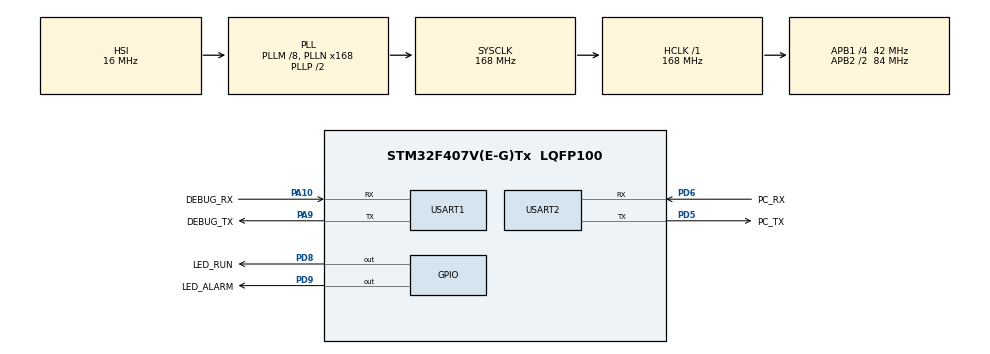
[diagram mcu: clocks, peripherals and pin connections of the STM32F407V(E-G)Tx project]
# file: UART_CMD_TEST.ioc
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Dma.Request0=USART1_RX
Dma.Request1=USART1_TX
Dma.Request2=USART2_RX
Dma.Request3=USART2_TX
Dma.USART1_RX.0.Direction=DMA_PERIPH_TO_MEMORY
Dma.USART1_RX.0.FIFOMode=DMA_FIFOMODE_DISABLE
Dma.USART1_RX.0.Instance=DMA2_Stream2
Dma.USART1_RX.0.MemDataAlignment=DMA_MDATAALIGN_BYTE
Dma.USART1_RX.0.MemInc=DMA_MINC_ENABLE
Dma.USART1_RX.0.Mode=DMA_NORMAL
Dma.USART1_RX.0.PeriphDataAlignment=DMA_PDATAALIGN_BYTE
Dma.USART1_RX.0.PeriphInc=DMA_PINC_DISABLE
Dma.USART1_RX.0.Priority=DMA_PRIORITY_HIGH
Dma.USART1_TX.1.Direction=DMA_MEMORY_TO_PERIPH
Dma.USART1_TX.1.FIFOMode=DMA_FIFOMODE_DISABLE
Dma.USART1_TX.1.Instance=DMA2_Stream7
Dma.USART1_TX.1.MemDataAlignment=DMA_MDATAALIGN_BYTE
Dma.USART1_TX.1.MemInc=DMA_MINC_ENABLE
Dma.USART1_TX.1.Mode=DMA_NORMAL
Dma.USART1_TX.1.PeriphDataAlignment=DMA_PDATAALIGN_BYTE
Dma.USART1_TX.1.PeriphInc=DMA_PINC_DISABLE
Dma.USART1_TX.1.Priority=DMA_PRIORITY_HIGH
Dma.USART2_RX.2.Direction=DMA_PERIPH_TO_MEMORY
Dma.USART2_RX.2.FIFOMode=DMA_FIFOMODE_DISABLE
Dma.USART2_RX.2.Instance=DMA1_Stream5
Dma.USART2_RX.2.MemDataAlignment=DMA_MDATAALIGN_BYTE
Dma.USART2_RX.2.MemInc=DMA_MINC_ENABLE
Dma.USART2_RX.2.Mode=DMA_NORMAL
Dma.USART2_RX.2.PeriphDataAlignment=DMA_PDATAALIGN_BYTE
Dma.USART2_RX.2.PeriphInc=DMA_PINC_DISABLE
Dma.USART2_RX.2.Priority=DMA_PRIORITY_MEDIUM
Dma.USART2_TX.3.Direction=DMA_MEMORY_TO_PERIPH
Dma.USART2_TX.3.FIFOMode=DMA_FIFOMODE_DISABLE
Dma.USART2_TX.3.Instance=DMA1_Stream6
Dma.USART2_TX.3.MemDataAlignment=DMA_MDATAALIGN_BYTE
Dma.USART2_TX.3.MemInc=DMA_MINC_ENABLE
Dma.USART2_TX.3.Mode=DMA_NORMAL
Dma.USART2_TX.3.PeriphDataAlignment=DMA_PDATAALIGN_BYTE
Dma.USART2_TX.3.PeriphInc=DMA_PINC_DISABLE
Dma.USART2_TX.3.Priority=DMA_PRIORITY_MEDIUM
FREERTOS.Mutexes01=PrintfMutex,Dynamic,NULL
FREERTOS.Queues01=U1RecvQueue,16,uint32_t,0,Dynamic,NULL,NULL;U2RecvQueue,16,uint32_t,0,Dynamic,NULL,NULL;U2SendQueue,16,uint32_t,0,Dynamic,NULL,NULL;U1SendQueue,16,uint32_t,0,Dynamic,NULL,NULL
FREERTOS.Tasks01=SysInitTask,0,512,StartSysInitTask,Default,NULL,Dynamic,NULL,NULL;DebugCmdTask,1,512,StartDebugCmdTask,Default,NULL,Dynamic,NULL,NULL;LedRunTask,0,128,StartLedRunTask,Default,NULL,Dynamic,NULL,NULL;Upload2PCTask,1,256,StartUpload2PCTask,Default,NULL,Dynamic,NULL,NULL
FREERTOS.configGENERATE_RUN_TIME_STATS=1
FREERTOS.configUSE_STATS_FORMATTING_FUNCTIONS=1
FREERTOS.configUSE_TIMERS=1
FREERTOS.configUSE_TRACE_FACILITY=1
Mcu.Family=STM32F4
Mcu.Name=STM32F407V(E-G)Tx
Mcu.Package=LQFP100
NVIC.DMA1_Stream5_IRQn=true\:5\:0\:false\:false\:true\:true\:false
NVIC.DMA1_Stream6_IRQn=true\:5\:0\:false\:false\:true\:true\:false
NVIC.DMA2_Stream2_IRQn=true\:5\:0\:false\:false\:true\:true\:false
NVIC.DMA2_Stream7_IRQn=true\:5\:0\:false\:false\:true\:true\:false
NVIC.PriorityGroup=NVIC_PRIORITYGROUP_4
NVIC.TIM5_IRQn=true\:0\:0\:false\:false\:true\:false\:false
NVIC.TIM6_DAC_IRQn=true\:5\:0\:false\:false\:true\:true\:true
NVIC.TimeBase=TIM5_IRQn
NVIC.TimeBaseIP=TIM5
NVIC.USART1_IRQn=true\:5\:0\:false\:false\:true\:true\:true
NVIC.USART2_IRQn=true\:5\:0\:false\:false\:true\:true\:true
PA10.GPIO_Label=DEBUG_RX
PA10.Mode=Asynchronous
PA10.Signal=USART1_RX
PA13.Mode=Serial_Wire
PA13.Signal=SYS_JTMS-SWDIO
PA14.Mode=Serial_Wire
PA14.Signal=SYS_JTCK-SWCLK
PA9.GPIO_Label=DEBUG_TX
PA9.Mode=Asynchronous
PA9.Signal=USART1_TX
PD5.GPIO_Label=PC_TX
PD5.Mode=Asynchronous
PD5.Signal=USART2_TX
PD6.GPIO_Label=PC_RX
PD6.Mode=Asynchronous
PD6.Signal=USART2_RX
PD8.GPIO_Label=LED_RUN
PD8.GPIO_ModeDefaultOutputPP=GPIO_MODE_OUTPUT_PP
PD8.GPIO_PuPd=GPIO_PULLDOWN
PD8.GPIO_Speed=GPIO_SPEED_FREQ_MEDIUM
PD8.PinState=GPIO_PIN_RESET
PD8.Signal=GPIO_Output
PD9.GPIO_Label=LED_ALARM
PD9.GPIO_PuPd=GPIO_PULLDOWN
PD9.GPIO_Speed=GPIO_SPEED_FREQ_MEDIUM
PD9.Signal=GPIO_Output
PH0-OSC_IN.Mode=HSE-External-Oscillator
PH0-OSC_IN.Signal=RCC_OSC_IN
PH1-OSC_OUT.Mode=HSE-External-Oscillator
PH1-OSC_OUT.Signal=RCC_OSC_OUT
ProjectManager.HeapSize=0x200
ProjectManager.StackSize=0x400
ProjectManager.TargetToolchain=MDK-ARM V5
RCC.48MHZClocksFreq_Value=84000000
RCC.AHBFreq_Value=168000000
RCC.APB1CLKDivider=RCC_HCLK_DIV4
RCC.APB1Freq_Value=42000000
RCC.APB1TimFreq_Value=84000000
RCC.APB2CLKDivider=RCC_HCLK_DIV2
RCC.APB2Freq_Value=84000000
RCC.APB2TimFreq_Value=168000000
RCC.CortexFreq_Value=168000000
RCC.HCLKFreq_Value=168000000
RCC.HSE_VALUE=8000000
RCC.HSI_VALUE=16000000
RCC.LSE_VALUE=32768
RCC.PLLM=8
RCC.PLLN=168
RCC.SYSCLKFreq_VALUE=168000000
RCC.SYSCLKSource=RCC_SYSCLKSOURCE_PLLCLK
RCC.VCOOutputFreq_Value=336000000
TIM6.Period=10
TIM6.Prescaler=84-1
USART1.VirtualMode=VM_ASYNC
USART2.VirtualMode=VM_ASYNC
VP_FREERTOS_VS_ENABLE.Mode=Enabled
VP_SYS_VS_tim5.Mode=TIM5
VP_TIM6_VS_ClockSourceINT.Mode=Enable_Timer
board=custom

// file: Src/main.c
/**
  ******************************************************************************
  * @file           : main.c
  * @brief          : Main program body
  ******************************************************************************
  * This notice applies to any and all portions of this file
  * that are not between comment pairs USER CODE BEGIN and
  * USER CODE END. Other portions of this file, whether
  * inserted by the user or by software development tools
  * are owned by their respective copyright owners.
  *
  * Copyright (c) 2020 STMicroelectronics International N.V.
  * All rights reserved.
  *
  * Redistribution and use in source and binary forms, with or without
  * modification, are permitted, provided that the following conditions are met:
  *
  * 1. Redistribution of source code must retain the above copyright notice,
  *    this list of conditions and the following disclaimer.
  * 2. Redistributions in binary form must reproduce the above copyright notice,
  *    this list of conditions and the following disclaimer in the documentation
  *    and/or other materials provided with the distribution.
  * 3. Neither the name of STMicroelectronics nor the names of other
  *    contributors to this software may be used to endorse or promote products
  *    derived from this software without specific written permission.
  * 4. This software, including modifications and/or derivative works of this
  *    software, must execute solely and exclusively on microcontroller or
  *    microprocessor devices manufactured by or for STMicroelectronics.
  * 5. Redistribution and use of this software other than as permitted under
  *    this license is void and will automatically terminate your rights under
  *    this license.
  *
  * THIS SOFTWARE IS PROVIDED BY STMICROELECTRONICS AND CONTRIBUTORS "AS IS"
  * AND ANY EXPRESS, IMPLIED OR STATUTORY WARRANTIES, INCLUDING, BUT NOT
  * LIMITED TO, THE IMPLIED WARRANTIES OF MERCHANTABILITY, FITNESS FOR A
  * PARTICULAR PURPOSE AND NON-INFRINGEMENT OF THIRD PARTY INTELLECTUAL PROPERTY
  * RIGHTS ARE DISCLAIMED TO THE FULLEST EXTENT PERMITTED BY LAW. IN NO EVENT
  * SHALL STMICROELECTRONICS OR CONTRIBUTORS BE LIABLE FOR ANY DIRECT, INDIRECT,
  * INCIDENTAL, SPECIAL, EXEMPLARY, OR CONSEQUENTIAL DAMAGES (INCLUDING, BUT NOT
  * LIMITED TO, PROCUREMENT OF SUBSTITUTE GOODS OR SERVICES; LOSS OF USE, DATA,
  * OR PROFITS; OR BUSINESS INTERRUPTION) HOWEVER CAUSED AND ON ANY THEORY OF
  * LIABILITY, WHETHER IN CONTRACT, STRICT LIABILITY, OR TORT (INCLUDING
  * NEGLIGENCE OR OTHERWISE) ARISING IN ANY WAY OUT OF THE USE OF THIS SOFTWARE,
  * EVEN IF ADVISED OF THE POSSIBILITY OF SUCH DAMAGE.
  *
  ******************************************************************************
  */
#include "main.h"
#include "stm32f4xx_hal.h"
#include "cmsis_os.h"
#include "dma.h"
#include "tim.h"
#include "usart.h"
#include "gpio.h"

/* USER CODE BEGIN PV */
/* Private variables ---------------------------------------------------------*/
extern volatile unsigned long  ulHighFrequencyTimerTicks;
/* USER CODE END PV */

void SystemClock_Config(void);
void MX_FREERTOS_Init(void);

/* USER CODE BEGIN PFP */
/* Private function prototypes -----------------------------------------------*/

/* USER CODE END PFP */

int main(void)
{

  /* MCU Configuration----------------------------------------------------------*/

  /* Reset of all peripherals, Initializes the Flash interface and the Systick. */
  HAL_Init();

  /* Configure the system clock */
  SystemClock_Config();

  /* Initialize all configured peripherals */
  MX_GPIO_Init();
  MX_DMA_Init();
  MX_USART1_UART_Init();
  MX_USART2_UART_Init();
  MX_TIM6_Init();

  /* Call init function for freertos objects (in freertos.c) */
  MX_FREERTOS_Init();

  /* Start scheduler */
  osKernelStart();

  /* We should never get here as control is now taken by the scheduler */

  /* Infinite loop */
  while (1)
  {

  }

}

void SystemClock_Config(void)
{

  RCC_OscInitTypeDef RCC_OscInitStruct;
  RCC_ClkInitTypeDef RCC_ClkInitStruct;

    /**Configure the main internal regulator output voltage
    */
  __HAL_RCC_PWR_CLK_ENABLE();

  __HAL_PWR_VOLTAGESCALING_CONFIG(PWR_REGULATOR_VOLTAGE_SCALE1);

    /**Initializes the CPU, AHB and APB busses clocks
    */
  RCC_OscInitStruct.OscillatorType = RCC_OSCILLATORTYPE_HSI;
  RCC_OscInitStruct.HSIState = RCC_HSI_ON;
  RCC_OscInitStruct.HSICalibrationValue = 16;
  RCC_OscInitStruct.PLL.PLLState = RCC_PLL_ON;
  RCC_OscInitStruct.PLL.PLLSource = RCC_PLLSOURCE_HSI;
  RCC_OscInitStruct.PLL.PLLM = 8;
  RCC_OscInitStruct.PLL.PLLN = 168;
  RCC_OscInitStruct.PLL.PLLP = RCC_PLLP_DIV2;
  RCC_OscInitStruct.PLL.PLLQ = 4;
  if (HAL_RCC_OscConfig(&RCC_OscInitStruct) != HAL_OK)
  {
    _Error_Handler(__FILE__, __LINE__);
  }

    /**Initializes the CPU, AHB and APB busses clocks
    */
  RCC_ClkInitStruct.ClockType = RCC_CLOCKTYPE_HCLK|RCC_CLOCKTYPE_SYSCLK
                              |RCC_CLOCKTYPE_PCLK1|RCC_CLOCKTYPE_PCLK2;
  RCC_ClkInitStruct.SYSCLKSource = RCC_SYSCLKSOURCE_PLLCLK;
  RCC_ClkInitStruct.AHBCLKDivider = RCC_SYSCLK_DIV1;
  RCC_ClkInitStruct.APB1CLKDivider = RCC_HCLK_DIV4;
  RCC_ClkInitStruct.APB2CLKDivider = RCC_HCLK_DIV2;

  if (HAL_RCC_ClockConfig(&RCC_ClkInitStruct, FLASH_LATENCY_5) != HAL_OK)
  {
    _Error_Handler(__FILE__, __LINE__);
  }

    /**Configure the Systick interrupt time
    */
  HAL_SYSTICK_Config(HAL_RCC_GetHCLKFreq()/1000);

    /**Configure the Systick
    */
  HAL_SYSTICK_CLKSourceConfig(SYSTICK_CLKSOURCE_HCLK);

  /* SysTick_IRQn interrupt configuration */
  HAL_NVIC_SetPriority(SysTick_IRQn, 15, 0);
}

void HAL_TIM_PeriodElapsedCallback(TIM_HandleTypeDef *htim)
{
  if (htim->Instance == TIM5) {
    HAL_IncTick();
  }
  /* USER CODE BEGIN Callback 1 */
  if (htim->Instance == TIM6) {
     ulHighFrequencyTimerTicks++;
  }

  /* USER CODE END Callback 1 */
}

void _Error_Handler(char *file, int line)
{
  while(1)
  {
  }
}

/************************ (C) COPYRIGHT STMicroelectronics *****END OF FILE****/

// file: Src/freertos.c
/* USER CODE BEGIN Header */
/**
  ******************************************************************************
  * File Name          : freertos.c
  * Description        : Code for freertos applications
  ******************************************************************************
  * This notice applies to any and all portions of this file
  * that are not between comment pairs USER CODE BEGIN and
  * USER CODE END. Other portions of this file, whether
  * inserted by the user or by software development tools
  * are owned by their respective copyright owners.
  *
  * Copyright (c) 2020 STMicroelectronics International N.V.
  * All rights reserved.
  *
  * Redistribution and use in source and binary forms, with or without
  * modification, are permitted, provided that the following conditions are met:
  *
  * 1. Redistribution of source code must retain the above copyright notice,
  *    this list of conditions and the following disclaimer.
  * 2. Redistributions in binary form must reproduce the above copyright notice,
  *    this list of conditions and the following disclaimer in the documentation
  *    and/or other materials provided with the distribution.
  * 3. Neither the name of STMicroelectronics nor the names of other
  *    contributors to this software may be used to endorse or promote products
  *    derived from this software without specific written permission.
  * 4. This software, including modifications and/or derivative works of this
  *    software, must execute solely and exclusively on microcontroller or
  *    microprocessor devices manufactured by or for STMicroelectronics.
  * 5. Redistribution and use of this software other than as permitted under
  *    this license is void and will automatically terminate your rights under
  *    this license.
  *
  * THIS SOFTWARE IS PROVIDED BY STMICROELECTRONICS AND CONTRIBUTORS "AS IS"
  * AND ANY EXPRESS, IMPLIED OR STATUTORY WARRANTIES, INCLUDING, BUT NOT
  * LIMITED TO, THE IMPLIED WARRANTIES OF MERCHANTABILITY, FITNESS FOR A
  * PARTICULAR PURPOSE AND NON-INFRINGEMENT OF THIRD PARTY INTELLECTUAL PROPERTY
  * RIGHTS ARE DISCLAIMED TO THE FULLEST EXTENT PERMITTED BY LAW. IN NO EVENT
  * SHALL STMICROELECTRONICS OR CONTRIBUTORS BE LIABLE FOR ANY DIRECT, INDIRECT,
  * INCIDENTAL, SPECIAL, EXEMPLARY, OR CONSEQUENTIAL DAMAGES (INCLUDING, BUT NOT
  * LIMITED TO, PROCUREMENT OF SUBSTITUTE GOODS OR SERVICES; LOSS OF USE, DATA,
  * OR PROFITS; OR BUSINESS INTERRUPTION) HOWEVER CAUSED AND ON ANY THEORY OF
  * LIABILITY, WHETHER IN CONTRACT, STRICT LIABILITY, OR TORT (INCLUDING
  * NEGLIGENCE OR OTHERWISE) ARISING IN ANY WAY OUT OF THE USE OF THIS SOFTWARE,
  * EVEN IF ADVISED OF THE POSSIBILITY OF SUCH DAMAGE.
  *
  ******************************************************************************
  */
/* USER CODE END Header */

#include "FreeRTOS.h"
#include "task.h"
#include "main.h"
#include "cmsis_os.h"

/* USER CODE BEGIN Includes */
#include "app.h"

/* USER CODE END Includes */

/* USER CODE BEGIN Variables */
volatile unsigned long  ulHighFrequencyTimerTicks;
osMutexId U2PrintfMutexHandle;
/* USER CODE END Variables */
osThreadId SysInitTaskHandle;
osThreadId DebugCmdTaskHandle;
osThreadId LedRunTaskHandle;
osThreadId Upload2PCTaskHandle;
osMessageQId U1RecvQueueHandle;
osMessageQId U2RecvQueueHandle;
osMessageQId U2SendQueueHandle;
osMessageQId U1SendQueueHandle;
osMutexId PrintfMutexHandle;

void StartSysInitTask(void const * argument);
void StartDebugCmdTask(void const * argument);
void StartLedRunTask(void const * argument);
void StartUpload2PCTask(void const * argument);

void MX_FREERTOS_Init(void); /* (MISRA C 2004 rule 8.1) */

/* Hook prototypes */
void configureTimerForRunTimeStats(void);
unsigned long getRunTimeCounterValue(void);

/* USER CODE BEGIN 1 */
/* Functions needed when configGENERATE_RUN_TIME_STATS is on */
__weak void configureTimerForRunTimeStats(void)
{
	ulHighFrequencyTimerTicks = 0ul;
}

__weak unsigned long getRunTimeCounterValue(void)
{
	return ulHighFrequencyTimerTicks;
}
/* USER CODE END 1 */

void MX_FREERTOS_Init(void) {

  /* Create the mutex(es) */
  /* definition and creation of PrintfMutex */
  osMutexDef(PrintfMutex);
  PrintfMutexHandle = osMutexCreate(osMutex(PrintfMutex));

  /* USER CODE BEGIN RTOS_MUTEX */
  /* add mutexes, ... */
	  osMutexDef(U2PrintfMutex);
  U2PrintfMutexHandle = osMutexCreate(osMutex(U2PrintfMutex));
  /* USER CODE END RTOS_MUTEX */

  /* Create the thread(s) */
  /* definition and creation of SysInitTask */
  osThreadDef(SysInitTask, StartSysInitTask, osPriorityNormal, 0, 512);
  SysInitTaskHandle = osThreadCreate(osThread(SysInitTask), NULL);

  /* definition and creation of DebugCmdTask */
//  osThreadDef(DebugCmdTask, StartDebugCmdTask, osPriorityAboveNormal, 0, 512);
//  DebugCmdTaskHandle = osThreadCreate(osThread(DebugCmdTask), NULL);

//  /* definition and creation of LedRunTask */
//  osThreadDef(LedRunTask, StartLedRunTask, osPriorityNormal, 0, 128);
//  LedRunTaskHandle = osThreadCreate(osThread(LedRunTask), NULL);

//  /* definition and creation of Upload2PCTask */
//  osThreadDef(Upload2PCTask, StartUpload2PCTask, osPriorityAboveNormal, 0, 256);
//  Upload2PCTaskHandle = osThreadCreate(osThread(Upload2PCTask), NULL);

  /* Create the queue(s) */
  /* definition and creation of U1RecvQueue */
/* what about the sizeof here??? cd native code */
  osMessageQDef(U1RecvQueue, 16, uint32_t);
  U1RecvQueueHandle = osMessageCreate(osMessageQ(U1RecvQueue), NULL);

  /* definition and creation of U2RecvQueue */
/* what about the sizeof here??? cd native code */
  osMessageQDef(U2RecvQueue, 16, uint32_t);
  U2RecvQueueHandle = osMessageCreate(osMessageQ(U2RecvQueue), NULL);

  /* definition and creation of U2SendQueue */
/* what about the sizeof here??? cd native code */
  osMessageQDef(U2SendQueue, 16, uint32_t);
  U2SendQueueHandle = osMessageCreate(osMessageQ(U2SendQueue), NULL);

  /* definition and creation of U1SendQueue */
/* what about the sizeof here??? cd native code */
  osMessageQDef(U1SendQueue, 16, uint32_t);
  U1SendQueueHandle = osMessageCreate(osMessageQ(U1SendQueue), NULL);

}

void StartSysInitTask(void const * argument)
{

  /* USER CODE BEGIN StartSysInitTask */
  /* Infinite loop */
  for(;;)
  {
    ProcessSysInit();
  }
  /* USER CODE END StartSysInitTask */
}

void StartDebugCmdTask(void const * argument)
{
  /* USER CODE BEGIN StartDebugCmdTask */
  /* Infinite loop */
  for(;;)
  {
    ProcessDebugCmdTask();
  }
  /* USER CODE END StartDebugCmdTask */
}

void StartLedRunTask(void const * argument)
{
  /* USER CODE BEGIN StartLedRunTask */
  /* Infinite loop */
  for(;;)
  {
	ProcessLedRun();
  }
  /* USER CODE END StartLedRunTask */
}

void StartUpload2PCTask(void const * argument)
{
  for(;;)
  {
    osDelay(1);
  }
}

/************************ (C) COPYRIGHT STMicroelectronics *****END OF FILE****/
